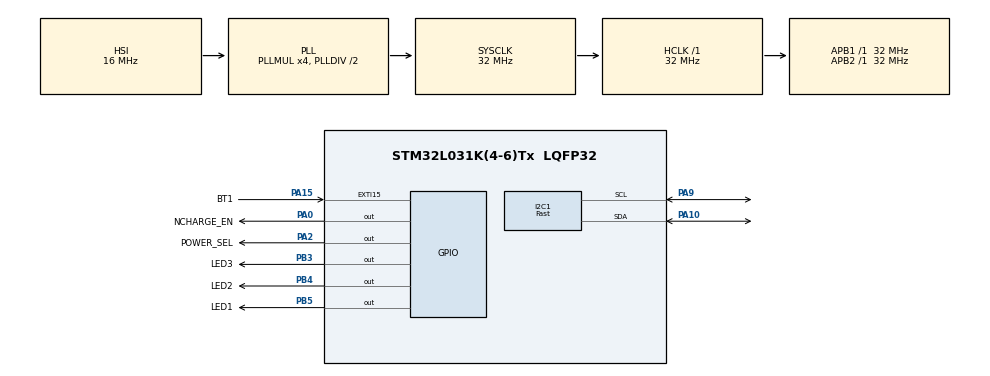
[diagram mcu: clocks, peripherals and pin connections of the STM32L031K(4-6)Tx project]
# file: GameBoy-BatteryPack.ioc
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I2C1.I2C_Fall_Time=150
I2C1.I2C_Rise_Time=150
I2C1.I2C_Speed_Mode=I2C_Fast
I2C1.Speed=100
I2C1.Timing=0x2021154E
Mcu.Family=STM32L0
Mcu.Name=STM32L031K(4-6)Tx
Mcu.Package=LQFP32
NVIC.EXTI4_15_IRQn=true\:0\:0\:false\:false\:false\:true\:true\:true
NVIC.TIM21_IRQn=true\:0\:0\:false\:false\:false\:true\:true\:true
NVIC.TIM22_IRQn=true\:0\:0\:false\:false\:false\:true\:true\:true
PA0-CK_IN.GPIO_Label=NCHARGE_EN
PA0-CK_IN.Signal=GPIO_Output
PA10.GPIO_Pu=GPIO_NOPULL
PA10.Mode=I2C
PA10.Signal=I2C1_SDA
PA15.GPIO_Label=BT1
PA15.GPIO_PuPd=GPIO_PULLUP
PA15.Signal=GPXTI15
PA2.GPIO_Label=POWER_SEL
PA2.PinState=GPIO_PIN_SET
PA2.Signal=GPIO_Output
PA9.GPIO_Pu=GPIO_NOPULL
PA9.Mode=I2C
PA9.Signal=I2C1_SCL
PB3.GPIO_Label=LED3
PB3.Signal=GPIO_Output
PB4.GPIO_Label=LED2
PB4.Signal=GPIO_Output
PB5.GPIO_Label=LED1
PB5.PinState=GPIO_PIN_RESET
PB5.Signal=GPIO_Output
ProjectManager.HeapSize=0x200
ProjectManager.StackSize=0x400
ProjectManager.TargetToolchain=STM32CubeIDE
RCC.AHBFreq_Value=32000000
RCC.APB1Freq_Value=32000000
RCC.APB1TimFreq_Value=32000000
RCC.APB2Freq_Value=32000000
RCC.APB2TimFreq_Value=32000000
RCC.HCLKFreq_Value=32000000
RCC.HSE_VALUE=8000000
RCC.HSI16_VALUE=16000000
RCC.HSI_VALUE=16000000
RCC.LSE_VALUE=32768
RCC.MSI_VALUE=2097000
RCC.PLLMUL=RCC_PLLMUL_4
RCC.RCC_TIM_PRescaler_Selection=RCC_TIMPRES_DESACTIVATED
RCC.SYSCLKFreq_VALUE=32000000
RCC.SYSCLKSource=RCC_SYSCLKSOURCE_PLLCLK
RCC.VCOOutputFreq_Value=64000000
TIM21.AutoReloadPreload=TIM_AUTORELOAD_PRELOAD_ENABLE
TIM21.Period=100
TIM21.Prescaler=32-1
TIM22.Period=62499
TIM22.Prescaler=511
VP_TIM21_VS_ClockSourceINT.Mode=Internal
VP_TIM22_VS_ClockSourceINT.Mode=Internal
board=custom

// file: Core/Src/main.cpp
/* USER CODE BEGIN Header */
/**
  ******************************************************************************
  * @file           : main.c
  * @brief          : Main program body
  ******************************************************************************
  * @attention
  *
  * Copyright (c) 2025 STMicroelectronics.
  * All rights reserved.
  *
  * This software is licensed under terms that can be found in the LICENSE file
  * in the root directory of this software component.
  * If no LICENSE file comes with this software, it is provided AS-IS.
  *
  ******************************************************************************
  */
/* USER CODE END Header */
#include "main.h"

/* USER CODE BEGIN Includes */
#include "gbakku.h"
#include "twi.h"
/* USER CODE END Includes */

I2C_HandleTypeDef hi2c1;

TIM_HandleTypeDef htim21;
TIM_HandleTypeDef htim22;

void SystemClock_Config(void);
static void MX_GPIO_Init(void);
static void MX_I2C1_Init(void);
static void MX_TIM21_Init(void);
static void MX_TIM22_Init(void);

int main(void)
{

  /* MCU Configuration--------------------------------------------------------*/

  /* Reset of all peripherals, Initializes the Flash interface and the Systick. */
  HAL_Init();

  /* Configure the system clock */
  SystemClock_Config();

  /* Initialize all configured peripherals */
  MX_GPIO_Init();
  MX_I2C1_Init();
  MX_TIM21_Init();
  MX_TIM22_Init();

  /* Infinite loop */
  /* USER CODE BEGIN WHILE */
  HAL_TIM_Base_Start_IT(&htim21);
  gbakku akkuApp;
  akkuApp.init();
  while (1)
  {
    /* USER CODE END WHILE */

    /* USER CODE BEGIN 3 */
	  akkuApp.run();
  }
  /* USER CODE END 3 */
}

void SystemClock_Config(void)
{
  RCC_OscInitTypeDef RCC_OscInitStruct = {0};
  RCC_ClkInitTypeDef RCC_ClkInitStruct = {0};
  RCC_PeriphCLKInitTypeDef PeriphClkInit = {0};

  /** Configure the main internal regulator output voltage
  */
  __HAL_PWR_VOLTAGESCALING_CONFIG(PWR_REGULATOR_VOLTAGE_SCALE1);

  /** Initializes the RCC Oscillators according to the specified parameters
  * in the RCC_OscInitTypeDef structure.
  */
  RCC_OscInitStruct.OscillatorType = RCC_OSCILLATORTYPE_HSI;
  RCC_OscInitStruct.HSIState = RCC_HSI_ON;
  RCC_OscInitStruct.HSICalibrationValue = RCC_HSICALIBRATION_DEFAULT;
  RCC_OscInitStruct.PLL.PLLState = RCC_PLL_ON;
  RCC_OscInitStruct.PLL.PLLSource = RCC_PLLSOURCE_HSI;
  RCC_OscInitStruct.PLL.PLLMUL = RCC_PLLMUL_4;
  RCC_OscInitStruct.PLL.PLLDIV = RCC_PLLDIV_2;
  if (HAL_RCC_OscConfig(&RCC_OscInitStruct) != HAL_OK)
  {
    Error_Handler();
  }

  /** Initializes the CPU, AHB and APB buses clocks
  */
  RCC_ClkInitStruct.ClockType = RCC_CLOCKTYPE_HCLK|RCC_CLOCKTYPE_SYSCLK
                              |RCC_CLOCKTYPE_PCLK1|RCC_CLOCKTYPE_PCLK2;
  RCC_ClkInitStruct.SYSCLKSource = RCC_SYSCLKSOURCE_PLLCLK;
  RCC_ClkInitStruct.AHBCLKDivider = RCC_SYSCLK_DIV1;
  RCC_ClkInitStruct.APB1CLKDivider = RCC_HCLK_DIV1;
  RCC_ClkInitStruct.APB2CLKDivider = RCC_HCLK_DIV1;

  if (HAL_RCC_ClockConfig(&RCC_ClkInitStruct, FLASH_LATENCY_1) != HAL_OK)
  {
    Error_Handler();
  }
  PeriphClkInit.PeriphClockSelection = RCC_PERIPHCLK_I2C1;
  PeriphClkInit.I2c1ClockSelection = RCC_I2C1CLKSOURCE_PCLK1;
  if (HAL_RCCEx_PeriphCLKConfig(&PeriphClkInit) != HAL_OK)
  {
    Error_Handler();
  }
}

static void MX_I2C1_Init(void)
{

  hi2c1.Instance = I2C1;
  hi2c1.Init.Timing = 0x2021154E;
  hi2c1.Init.OwnAddress1 = 0;
  hi2c1.Init.AddressingMode = I2C_ADDRESSINGMODE_7BIT;
  hi2c1.Init.DualAddressMode = I2C_DUALADDRESS_DISABLE;
  hi2c1.Init.OwnAddress2 = 0;
  hi2c1.Init.OwnAddress2Masks = I2C_OA2_NOMASK;
  hi2c1.Init.GeneralCallMode = I2C_GENERALCALL_DISABLE;
  hi2c1.Init.NoStretchMode = I2C_NOSTRETCH_DISABLE;
  if (HAL_I2C_Init(&hi2c1) != HAL_OK)
  {
    Error_Handler();
  }

  /** Configure Analogue filter
  */
  if (HAL_I2CEx_ConfigAnalogFilter(&hi2c1, I2C_ANALOGFILTER_ENABLE) != HAL_OK)
  {
    Error_Handler();
  }

  /** Configure Digital filter
  */
  if (HAL_I2CEx_ConfigDigitalFilter(&hi2c1, 0) != HAL_OK)
  {
    Error_Handler();
  }

}

static void MX_TIM21_Init(void)
{

  TIM_ClockConfigTypeDef sClockSourceConfig = {0};
  TIM_MasterConfigTypeDef sMasterConfig = {0};

  htim21.Instance = TIM21;
  htim21.Init.Prescaler = 32-1;
  htim21.Init.CounterMode = TIM_COUNTERMODE_UP;
  htim21.Init.Period = 100;
  htim21.Init.ClockDivision = TIM_CLOCKDIVISION_DIV1;
  htim21.Init.AutoReloadPreload = TIM_AUTORELOAD_PRELOAD_ENABLE;
  if (HAL_TIM_Base_Init(&htim21) != HAL_OK)
  {
    Error_Handler();
  }
  sClockSourceConfig.ClockSource = TIM_CLOCKSOURCE_INTERNAL;
  if (HAL_TIM_ConfigClockSource(&htim21, &sClockSourceConfig) != HAL_OK)
  {
    Error_Handler();
  }
  sMasterConfig.MasterOutputTrigger = TIM_TRGO_RESET;
  sMasterConfig.MasterSlaveMode = TIM_MASTERSLAVEMODE_DISABLE;
  if (HAL_TIMEx_MasterConfigSynchronization(&htim21, &sMasterConfig) != HAL_OK)
  {
    Error_Handler();
  }

}

static void MX_TIM22_Init(void)
{

  TIM_ClockConfigTypeDef sClockSourceConfig = {0};
  TIM_MasterConfigTypeDef sMasterConfig = {0};

  htim22.Instance = TIM22;
  htim22.Init.Prescaler = 511;
  htim22.Init.CounterMode = TIM_COUNTERMODE_UP;
  htim22.Init.Period = 62499;
  htim22.Init.ClockDivision = TIM_CLOCKDIVISION_DIV1;
  htim22.Init.AutoReloadPreload = TIM_AUTORELOAD_PRELOAD_DISABLE;
  if (HAL_TIM_Base_Init(&htim22) != HAL_OK)
  {
    Error_Handler();
  }
  sClockSourceConfig.ClockSource = TIM_CLOCKSOURCE_INTERNAL;
  if (HAL_TIM_ConfigClockSource(&htim22, &sClockSourceConfig) != HAL_OK)
  {
    Error_Handler();
  }
  sMasterConfig.MasterOutputTrigger = TIM_TRGO_RESET;
  sMasterConfig.MasterSlaveMode = TIM_MASTERSLAVEMODE_DISABLE;
  if (HAL_TIMEx_MasterConfigSynchronization(&htim22, &sMasterConfig) != HAL_OK)
  {
    Error_Handler();
  }

}

static void MX_GPIO_Init(void)
{
  LL_EXTI_InitTypeDef EXTI_InitStruct = {0};
  LL_GPIO_InitTypeDef GPIO_InitStruct = {0};

  /* GPIO Ports Clock Enable */
  LL_IOP_GRP1_EnableClock(LL_IOP_GRP1_PERIPH_GPIOA);
  LL_IOP_GRP1_EnableClock(LL_IOP_GRP1_PERIPH_GPIOB);

  /**/
  LL_GPIO_ResetOutputPin(NCHARGE_EN_GPIO_Port, NCHARGE_EN_Pin);

  /**/
  LL_GPIO_ResetOutputPin(LED3_GPIO_Port, LED3_Pin);

  /**/
  LL_GPIO_ResetOutputPin(LED2_GPIO_Port, LED2_Pin);

  /**/
  LL_GPIO_ResetOutputPin(LED1_GPIO_Port, LED1_Pin);

  /**/
  LL_GPIO_SetOutputPin(POWER_SEL_GPIO_Port, POWER_SEL_Pin);

  /**/
  GPIO_InitStruct.Pin = NCHARGE_EN_Pin;
  GPIO_InitStruct.Mode = LL_GPIO_MODE_OUTPUT;
  GPIO_InitStruct.Speed = LL_GPIO_SPEED_FREQ_LOW;
  GPIO_InitStruct.OutputType = LL_GPIO_OUTPUT_PUSHPULL;
  GPIO_InitStruct.Pull = LL_GPIO_PULL_NO;
  LL_GPIO_Init(NCHARGE_EN_GPIO_Port, &GPIO_InitStruct);

  /**/
  GPIO_InitStruct.Pin = POWER_SEL_Pin;
  GPIO_InitStruct.Mode = LL_GPIO_MODE_OUTPUT;
  GPIO_InitStruct.Speed = LL_GPIO_SPEED_FREQ_LOW;
  GPIO_InitStruct.OutputType = LL_GPIO_OUTPUT_PUSHPULL;
  GPIO_InitStruct.Pull = LL_GPIO_PULL_NO;
  LL_GPIO_Init(POWER_SEL_GPIO_Port, &GPIO_InitStruct);

  /**/
  GPIO_InitStruct.Pin = LED3_Pin;
  GPIO_InitStruct.Mode = LL_GPIO_MODE_OUTPUT;
  GPIO_InitStruct.Speed = LL_GPIO_SPEED_FREQ_LOW;
  GPIO_InitStruct.OutputType = LL_GPIO_OUTPUT_PUSHPULL;
  GPIO_InitStruct.Pull = LL_GPIO_PULL_NO;
  LL_GPIO_Init(LED3_GPIO_Port, &GPIO_InitStruct);

  /**/
  GPIO_InitStruct.Pin = LED2_Pin;
  GPIO_InitStruct.Mode = LL_GPIO_MODE_OUTPUT;
  GPIO_InitStruct.Speed = LL_GPIO_SPEED_FREQ_LOW;
  GPIO_InitStruct.OutputType = LL_GPIO_OUTPUT_PUSHPULL;
  GPIO_InitStruct.Pull = LL_GPIO_PULL_NO;
  LL_GPIO_Init(LED2_GPIO_Port, &GPIO_InitStruct);

  /**/
  GPIO_InitStruct.Pin = LED1_Pin;
  GPIO_InitStruct.Mode = LL_GPIO_MODE_OUTPUT;
  GPIO_InitStruct.Speed = LL_GPIO_SPEED_FREQ_LOW;
  GPIO_InitStruct.OutputType = LL_GPIO_OUTPUT_PUSHPULL;
  GPIO_InitStruct.Pull = LL_GPIO_PULL_NO;
  LL_GPIO_Init(LED1_GPIO_Port, &GPIO_InitStruct);

  /**/
  LL_SYSCFG_SetEXTISource(LL_SYSCFG_EXTI_PORTA, LL_SYSCFG_EXTI_LINE15);

  /**/
  LL_GPIO_SetPinPull(BT1_GPIO_Port, BT1_Pin, LL_GPIO_PULL_UP);

  /**/
  LL_GPIO_SetPinMode(BT1_GPIO_Port, BT1_Pin, LL_GPIO_MODE_INPUT);

  /**/
  EXTI_InitStruct.Line_0_31 = LL_EXTI_LINE_15;
  EXTI_InitStruct.LineCommand = ENABLE;
  EXTI_InitStruct.Mode = LL_EXTI_MODE_IT;
  EXTI_InitStruct.Trigger = LL_EXTI_TRIGGER_RISING;
  LL_EXTI_Init(&EXTI_InitStruct);

  /* EXTI interrupt init*/
  NVIC_SetPriority(EXTI4_15_IRQn, 0);
  NVIC_EnableIRQ(EXTI4_15_IRQn);

}

void Error_Handler(void)
{
  __disable_irq();
  while (1)
  {
  }
}
